# APM32F40x register map
File version: 1.0
CPU: CM4 r1p0, little endian, no MPU, no FPU, 3 interrupt priority bits
Registers are 32-bit, read-write, reset 0x0 unless marked. A register's access mark holds for its fields unless they carry their own. Offsets are from the block's base; [hi:lo] are bit positions; {n}, {i} and the like mark numbered series.

## TMR6 — Basic timers
Base 0x40001000
Same registers: TMR7 0x40001400
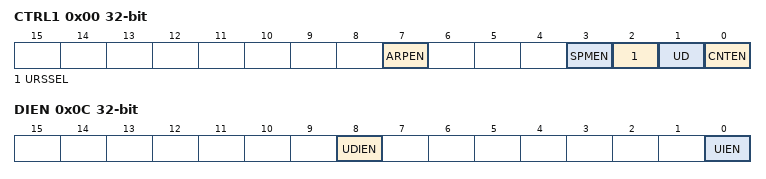
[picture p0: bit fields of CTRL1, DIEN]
0x00 CTRL1 — control register 1
  [7] ARPEN — Auto-reload preload enable
  [3] SPMEN — Single Pulse Mode Enable
  [2] URSSEL — Update request source
  [1] UD — Update disable
  [0] CNTEN — Counter enable
0x04 CTRL2 — control register 2
  [6:4] MMSEL — Master mode selection
0x0C DIEN — DMA/Interrupt enable register
  [8] UDIEN — Update DMA request enable
  [0] UIEN — Update interrupt enable
0x10 STS — status register
  [0] UIFLG — Update interrupt flag
0x14 CEG wo — event generation register
  [0] UEG — Update generation
0x24 CNT — counter
  [15:0] CNT — Counter value
0x28 PSC — prescaler
  [15:0] PSC — Prescaler value
0x2C AUTORLD — auto-reload register
  [15:0] AUTORLD — Auto-reload value

## EINT — External interrupt/event controller
Base 0x40013C00
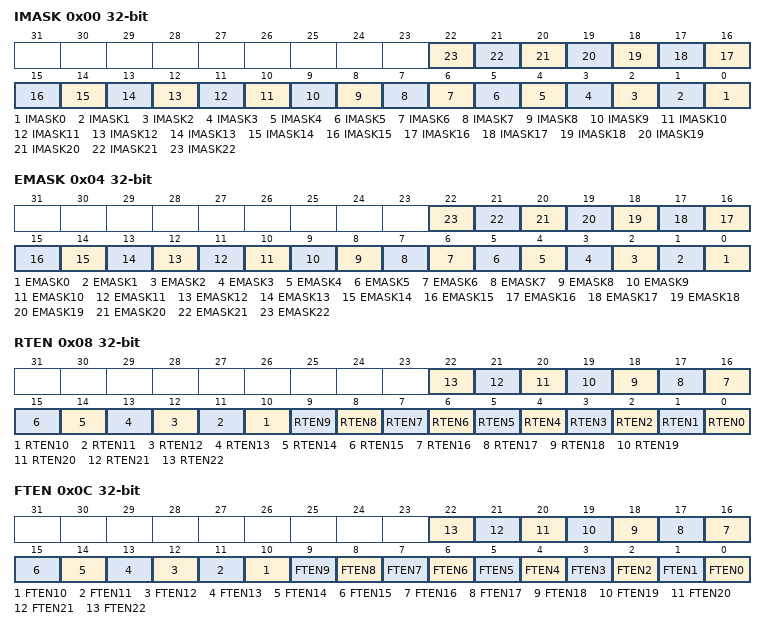
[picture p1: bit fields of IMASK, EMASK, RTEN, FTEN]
0x00 IMASK — Interrupt mask register
  [n] IMASK{n} (n=0..22) — Interrupt Mask on line {n}
0x04 EMASK — Event mask register
  [n] EMASK{n} (n=0..22) — Event Mask on line {n}
0x08 RTEN — Rising Trigger selection register
  [n] RTEN{n} (n=0..22) — Rising trigger event configuration of line {n}
0x0C FTEN — Falling Trigger selection register
  [n] FTEN{n} (n=0..22) — Falling trigger event configuration of line {n}
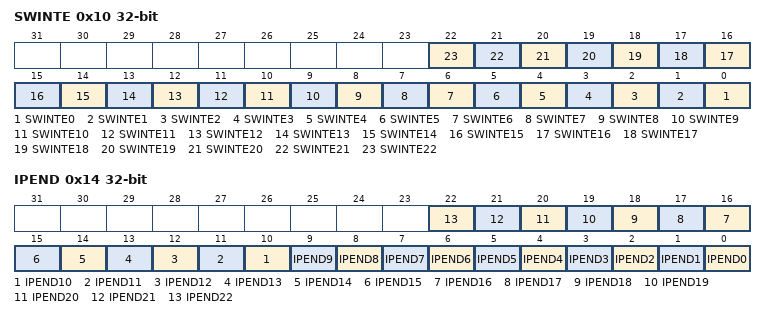
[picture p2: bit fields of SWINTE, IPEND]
0x10 SWINTE — Software interrupt event register
  [n] SWINTE{n} (n=0..22) — Software Interrupt on line {n}
0x14 IPEND — Pending register
  [n] IPEND{n} (n=0..22) — Pending bit {n}

## NVIC — Nested Vectored Interrupt Controller
Base 0xE000E100
{0x0+4i} ISER{i} (i=0..2) — Interrupt Set-Enable Register
  [31:0] SETENA
{0x80+4i} ICER{i} (i=0..2) — Interrupt Clear-Enable Register
  [31:0] CLRENA
{0x100+4i} ISPR{i} (i=0..2) — Interrupt Set-Pending Register
  [31:0] SETPEND
{0x180+4i} ICPR{i} (i=0..2) — Interrupt Clear-Pending Register
  [31:0] CLRPEND
{0x200+4i} IABR{i} ro (i=0..2) — Interrupt Active Bit Register
  [31:0] ACTIVE
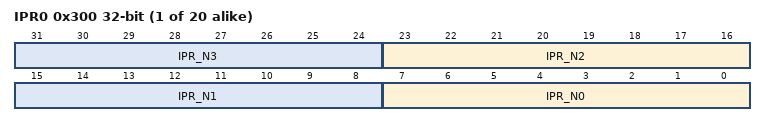
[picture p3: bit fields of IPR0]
{0x300+4i} IPR{i} (i=0..19) — Interrupt Priority Register
  [8n+7:8n] IPR_N{n} (n=0..3)

## Ethernet_MMC — Ethernet: MAC management counters
Base 0x40028100
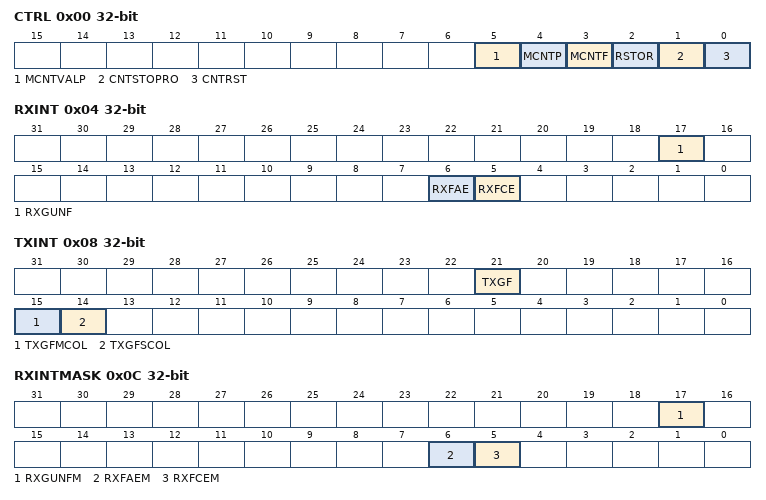
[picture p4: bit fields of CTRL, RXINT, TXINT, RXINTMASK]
0x00 CTRL — Ethernet MMC control register
  [5] MCNTVALP — MMC Counter Value Preset
  [4] MCNTP — MMC Counter Preset
  [3] MCNTF — MMC Counter Freeze
  [2] RSTOR — Reset on read
  [1] CNTSTOPRO — Counter Stop Rollover
  [0] CNTRST — Counter Reset
0x04 RXINT — Ethernet MMC receive interrupt register
  [17] RXGUNF — Received Good Unicast Frames
  [6] RXFAE — Received Frames Alignment Error
  [5] RXFCE — Received Frames CRC Error
0x08 TXINT ro — Ethernet MMC transmit interrupt register
  [21] TXGF — Transmitted Good Frames
  [15] TXGFMCOL — Transmitted Good Frames More Single Collision
  [14] TXGFSCOL — Transmitted Good Frames Single Collision
0x0C RXINTMASK — Ethernet MMC receive interrupt mask register
  [17] RXGUNFM — Received Good Unicast Frames Mask
  [6] RXFAEM — Received Frames Alignment Error Mask
  [5] RXFCEM — Received Frames CRC Error Mask
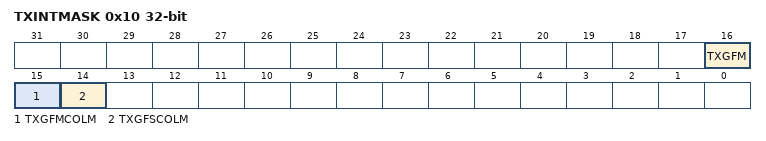
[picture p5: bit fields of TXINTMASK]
0x10 TXINTMASK — Ethernet MMC transmit interrupt mask register
  [16] TXGFM — Transmitted Good Frames Mask
  [15] TXGFMCOLM — ransmitted Good Frames More Single Collision Mask
  [14] TXGFSCOLM — Transmitted Good Frames Single Collision Mask
0x4C TXGFSCCNT ro — Ethernet MMC transmitted good frames after a single collision counter
  [31:0] TXGFSCCNT — Transmitted Good Frames Single Collision Counter
0x50 TXGFMCCNT ro — Ethernet MMC transmitted good frames after more than a single collision
  [31:0] TXGFMCCNT — Transmitted Good Frames More Collision Counter
0x68 TXGFCNT ro — Ethernet MMC transmitted good frames counter register
  [31:0] TXGFCNT — Transmitted Good Frames Counter
0x94 RXFCECNT ro — Ethernet MMC received frames with CRC error counter register
  [31:0] RXFCECNT — Received Frames CRC Error Counter
0x98 RXFAECNT ro — Ethernet MMC received frames with alignment error counter register
  [31:0] RXFAECNT — Received Frames Alignment Error Counter
0xC4 RXGUNCNT ro — MMC received good unicast frames counter register
  [31:0] RXFCECNT — Received Good Unicast Frames Counter
